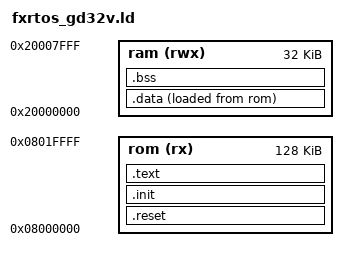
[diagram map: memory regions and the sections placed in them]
/*
 *  Copyright (C) JSC EREMEX, 2020.
 *  Redistribution and use in source and binary forms, with or without 
 *  modification, are permitted provided that the following conditions are met:
 *  1. Redistributions of source code must retain the above copyright notice,
 *     this list of conditions and the following disclaimer.
 *  2. Redistributions in binary form must reproduce the above copyright 
 *     notice, this list of conditions and the following disclaimer in the 
 *     documentation and/or other materials provided with the distribution.
 *  3. Neither the name of the copyright holder nor the names of its 
 *     contributors may be used to endorse or promote products derived from 
 *     this software without specific prior written permission.
 *  THIS SOFTWARE IS PROVIDED BY THE COPYRIGHT HOLDERS AND CONTRIBUTORS "AS IS"
 *  AND ANY EXPRESS OR IMPLIED WARRANTIES, INCLUDING, BUT NOT LIMITED TO, THE 
 *  IMPLIED WARRANTIES OF MERCHANTABILITY AND FITNESS FOR A PARTICULAR PURPOSE
 *  ARE DISCLAIMED. IN NO EVENT SHALL THE COPYRIGHT HOLDER OR CONTRIBUTORS BE 
 *  LIABLE FOR ANY DIRECT, INDIRECT, INCIDENTAL, SPECIAL, EXEMPLARY, OR 
 *  CONSEQUENTIAL DAMAGES (INCLUDING, BUT NOT LIMITED TO, PROCUREMENT OF 
 *  SUBSTITUTE GOODS OR SERVICES; LOSS OF USE, DATA, OR PROFITS; OR BUSINESS 
 *  INTERRUPTION) HOWEVER CAUSED AND ON ANY THEORY OF LIABILITY, WHETHER IN 
 *  CONTRACT, STRICT LIABILITY, OR TORT (INCLUDING NEGLIGENCE OR OTHERWISE)
 *  ARISING IN ANY WAY OUT OF THE USE OF THIS SOFTWARE, EVEN IF ADVISED OF THE
 *  POSSIBILITY OF SUCH DAMAGE. 
 */

MEMORY
{
	rom (rx) : ORIGIN = 0x08000000, LENGTH = 128K
	ram (rwx) : ORIGIN = 0x20000000, LENGTH = 32K
}

ENTRY(reset_handler)

SECTIONS
{
	.reset : {
		*(.reset)
		*(.vectors)
	} >rom
        
    .init : {
		*(.init)
	} >rom

	.text : {
		*(.text*)
		. = ALIGN(4);
		*(.rodata*)
		*(.srodata*)
		. = ALIGN(4);
	} >rom

	. = ALIGN(4);
	_etext = .;

	.data : {
		_data = .;
		*(.data*)
		*(.sdata*)
	} >ram AT >rom
	_data_loadaddr = LOADADDR(.data);

	. = ALIGN(4);
	_edata = .;

	.bss : {
                _bss = .;
		*(.bss*)
		*(.sbss*)
		*(COMMON)
		. = ALIGN(4);
		_ebss = .;
	} >ram

	. = ALIGN(4);
	end = .;
}
